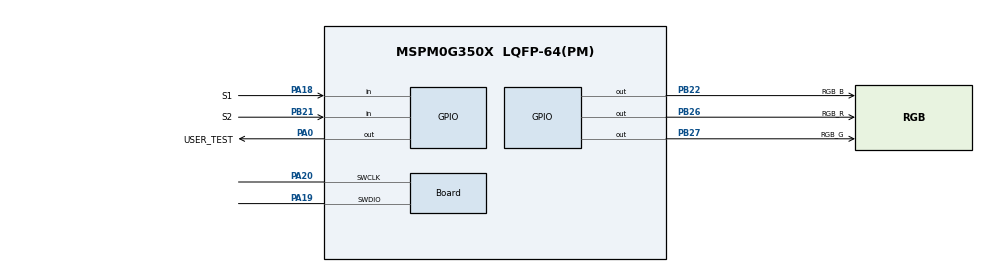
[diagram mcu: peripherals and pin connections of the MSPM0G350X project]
/**
 * @cliArgs --device "MSPM0G350X" --package "LQFP-64(PM)" --part "Default" --product "mspm0_sdk@2.00.01.00"
 * @versions {"tool":"1.20.0+3587"}
 */

/**
 * Import the modules used in this configuration.
 */
const GPIO          = scripting.addModule("/ti/driverlib/GPIO", {}, false);
const GPIO1         = GPIO.addInstance();
const GPIO2         = GPIO.addInstance();
const GPIO3         = GPIO.addInstance();
const SYSCTL        = scripting.addModule("/ti/driverlib/SYSCTL");
const ProjectConfig = scripting.addModule("/ti/project_config/ProjectConfig");

/**
 * Write custom configuration values to the imported modules.
 */
GPIO1.$name                         = "GPIO_LEDS";
GPIO1.port                          = "PORTA";
GPIO1.associatedPins[0].$name       = "USER_TEST";
GPIO1.associatedPins[0].pin.$assign = "PA0";

const Board                       = scripting.addModule("/ti/driverlib/Board", {}, false);
Board.peripheral.$assign          = "DEBUGSS";
Board.peripheral.swclkPin.$assign = "PA20";
Board.peripheral.swdioPin.$assign = "PA19";

GPIO2.port                               = "PORTA";
GPIO2.$name                              = "KEY";
GPIO2.associatedPins[0].$name            = "S1";
GPIO2.associatedPins[0].direction        = "INPUT";
GPIO2.associatedPins[0].internalResistor = "PULL_DOWN";
GPIO2.associatedPins[0].pin.$assign      = "PA18";

GPIO3.$name                              = "PORTB";
GPIO3.associatedPins.create(4);
GPIO3.associatedPins[0].$name            = "RGB_R";
GPIO3.associatedPins[0].pin.$assign      = "PB26";
GPIO3.associatedPins[1].$name            = "RGB_G";
GPIO3.associatedPins[1].pin.$assign      = "PB27";
GPIO3.associatedPins[2].$name            = "RGB_B";
GPIO3.associatedPins[2].pin.$assign      = "PB22";
GPIO3.associatedPins[3].$name            = "S2";
GPIO3.associatedPins[3].direction        = "INPUT";
GPIO3.associatedPins[3].internalResistor = "PULL_UP";
GPIO3.associatedPins[3].pin.$assign      = "PB21";

SYSCTL.clockTreeEn = true;

ProjectConfig.deviceSpin = "MSPM0G3507";
